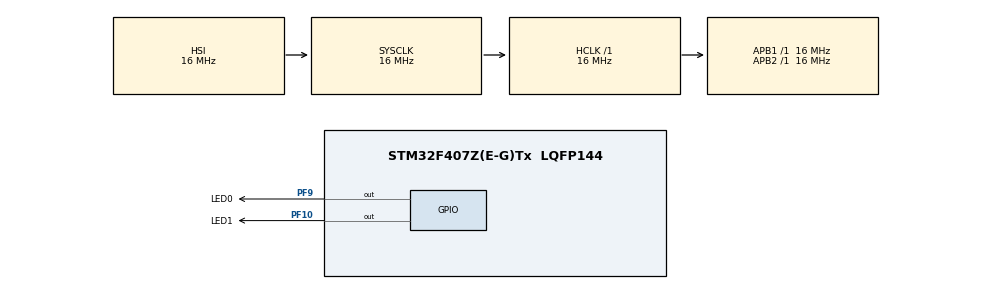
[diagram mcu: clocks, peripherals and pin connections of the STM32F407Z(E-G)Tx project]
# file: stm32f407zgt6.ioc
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Mcu.Family=STM32F4
Mcu.Name=STM32F407Z(E-G)Tx
Mcu.Package=LQFP144
NVIC.PriorityGroup=NVIC_PRIORITYGROUP_4
PF10.GPIO_Label=LED1
PF10.GPIO_Speed=GPIO_SPEED_FREQ_LOW
PF10.PinState=GPIO_PIN_RESET
PF10.Signal=GPIO_Output
PF9.GPIO_Label=LED0
PF9.PinState=GPIO_PIN_SET
PF9.Signal=GPIO_Output
ProjectManager.HeapSize=0x200
ProjectManager.StackSize=0x400
ProjectManager.TargetToolchain=STM32CubeIDE
RCC.AHBFreq_Value=16000000
RCC.APB1Freq_Value=16000000
RCC.APB2Freq_Value=16000000
RCC.CortexFreq_Value=16000000
RCC.HSE_VALUE=25000000
RCC.HSI_VALUE=16000000
RCC.LSE_VALUE=32768
RCC.SYSCLKFreq_VALUE=16000000
RCC.VCOOutputFreq_Value=192000000
board=custom

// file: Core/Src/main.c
/* USER CODE BEGIN Header */
/**
  ******************************************************************************
  * @file           : main.c
  * @brief          : Main program body
  ******************************************************************************
  * @attention
  *
  * Copyright (c) 2024 STMicroelectronics.
  * All rights reserved.
  *
  * This software is licensed under terms that can be found in the LICENSE file
  * in the root directory of this software component.
  * If no LICENSE file comes with this software, it is provided AS-IS.
  *
  ******************************************************************************
  */
/* USER CODE END Header */
#include "main.h"

/* USER CODE BEGIN Includes */
#include "FreeRTOS.h"
#include "task.h"
/* USER CODE END Includes */

/* USER CODE BEGIN PV */
TaskHandle_t TaskLed1Handler;
TaskHandle_t TaskLed2Handler;
/* USER CODE END PV */

void SystemClock_Config(void);
static void MX_GPIO_Init(void);
/* USER CODE BEGIN PFP */
void CDD_OperateMainfunc_LED1(void *arg);
void CDD_OperateMainfunc_LED2(void *arg);
static void MX_GPIO_Init(void);
/* USER CODE BEGIN PFP */

/* USER CODE END PFP */

int main(void)
{

  /* MCU Configuration--------------------------------------------------------*/

  /* Reset of all peripherals, Initializes the Flash interface and the Systick. */
  HAL_Init();

  /* Configure the system clock */
  SystemClock_Config();

  /* Initialize all configured peripherals */
  MX_GPIO_Init();
  /* USER CODE BEGIN 2 */
  xTaskCreate(CDD_OperateMainfunc_LED1, "LED1", 512, NULL, 1, TaskLed1Handler);
  xTaskCreate(CDD_OperateMainfunc_LED2, "LED1", 512, NULL, 1, TaskLed2Handler);
  vTaskStartScheduler();
  /* USER CODE END 2 */

  /* Infinite loop */
  while (1)
  {

  }
}

void SystemClock_Config(void)
{
  RCC_OscInitTypeDef RCC_OscInitStruct = {0};
  RCC_ClkInitTypeDef RCC_ClkInitStruct = {0};

  /** Configure the main internal regulator output voltage
  */
  __HAL_RCC_PWR_CLK_ENABLE();
  __HAL_PWR_VOLTAGESCALING_CONFIG(PWR_REGULATOR_VOLTAGE_SCALE1);

  /** Initializes the RCC Oscillators according to the specified parameters
  * in the RCC_OscInitTypeDef structure.
  */
  RCC_OscInitStruct.OscillatorType = RCC_OSCILLATORTYPE_HSI;
  RCC_OscInitStruct.HSIState = RCC_HSI_ON;
  RCC_OscInitStruct.HSICalibrationValue = RCC_HSICALIBRATION_DEFAULT;
  RCC_OscInitStruct.PLL.PLLState = RCC_PLL_NONE;
  if (HAL_RCC_OscConfig(&RCC_OscInitStruct) != HAL_OK)
  {
    Error_Handler();
  }

  /** Initializes the CPU, AHB and APB buses clocks
  */
  RCC_ClkInitStruct.ClockType = RCC_CLOCKTYPE_HCLK|RCC_CLOCKTYPE_SYSCLK
                              |RCC_CLOCKTYPE_PCLK1|RCC_CLOCKTYPE_PCLK2;
  RCC_ClkInitStruct.SYSCLKSource = RCC_SYSCLKSOURCE_HSI;
  RCC_ClkInitStruct.AHBCLKDivider = RCC_SYSCLK_DIV1;
  RCC_ClkInitStruct.APB1CLKDivider = RCC_HCLK_DIV1;
  RCC_ClkInitStruct.APB2CLKDivider = RCC_HCLK_DIV1;

  if (HAL_RCC_ClockConfig(&RCC_ClkInitStruct, FLASH_LATENCY_0) != HAL_OK)
  {
    Error_Handler();
  }
}

static void MX_GPIO_Init(void)
{
  GPIO_InitTypeDef GPIO_InitStruct = {0};

  /* GPIO Ports Clock Enable */
  __HAL_RCC_GPIOF_CLK_ENABLE();

  /*Configure GPIO pin Output Level */
  HAL_GPIO_WritePin(LED0_GPIO_Port, LED0_Pin, GPIO_PIN_SET);

  /*Configure GPIO pin Output Level */
  HAL_GPIO_WritePin(LED1_GPIO_Port, LED1_Pin, GPIO_PIN_RESET);

  /*Configure GPIO pins : LED0_Pin LED1_Pin */
  GPIO_InitStruct.Pin = LED0_Pin|LED1_Pin;
  GPIO_InitStruct.Mode = GPIO_MODE_OUTPUT_PP;
  GPIO_InitStruct.Pull = GPIO_NOPULL;
  GPIO_InitStruct.Speed = GPIO_SPEED_FREQ_LOW;
  HAL_GPIO_Init(GPIOF, &GPIO_InitStruct);

}

/* USER CODE BEGIN 4 */
void CDD_OperateMainfunc_LED1(void *arg)
{
  while(1)
  {
    HAL_GPIO_WritePin(GPIOF, GPIO_PIN_9, GPIO_PIN_SET);
    vTaskDelay(500);
    HAL_GPIO_WritePin(GPIOF, GPIO_PIN_9, GPIO_PIN_RESET);
    vTaskDelay(500);
  }
}
void CDD_OperateMainfunc_LED2(void *arg)
{
  while(1)
  {
    HAL_GPIO_WritePin(GPIOF, GPIO_PIN_10, GPIO_PIN_RESET);
    vTaskDelay(500);
    HAL_GPIO_WritePin(GPIOF, GPIO_PIN_10, GPIO_PIN_SET);
    vTaskDelay(500);
  }
}
/* USER CODE END 4 */

void Error_Handler(void)
{
  __disable_irq();
  while (1)
  {
  }
}
